# c71_DMC register map
Vendor: Texas Instruments
Peripheral module from a debugger description file (folder C71).
Registers are 64-bit, access per field, reset 0x0 unless marked. A register's access mark holds for its fields unless they carry their own. Offsets are as the file gives them; lines under a group give offsets from that group; [hi:lo] are bit positions; {n}, {i} and the like mark numbered series; 'fields as' and 'values as' point back to an identical list; <NAME> marks a mode.

## DMC(L1D) — Data Memory Controller
0x200 L1DCFG reset 0x7 — L1D Cache Configuration Register
  [2:0] L1DMODE rw — Controls the L1D Cache Size Mode
0x202 L1DWB — L1D Global Writeback Register
  [0] WB rw — Controls the Global Writeback of L1D Cache
0x203 L1DWBINV — L1D Global Writeback Invalidate Register
  [0] WBINV rw — Writeback and invalidate all lines L1D Cache
0x204 L1DINV — L1D Invalidate Register
  [0] INV rw — Controls the Global Invalidation of L1D Cache
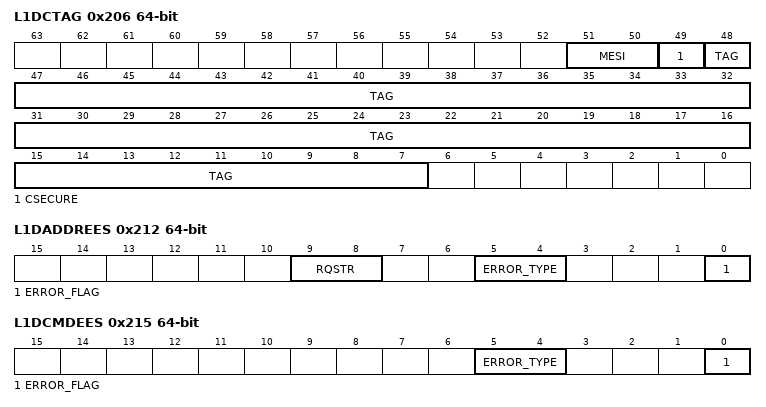
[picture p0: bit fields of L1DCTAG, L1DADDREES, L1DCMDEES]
0x206 L1DCTAG ro — L1D Cache tag View
  [51:50] MESI — MESI Bits includes valid and dirty bits
  [49] CSECURE — Secure bit
  [48:7] TAG
0x211 L1DADDREEA ro — L1D Addressing Error Event Address
  [43:0] EADDR — Transaction address for which error was detected
0x212 L1DADDREES ro — L1D Addressing Error Event Status
  [9:8] RQSTR — Requestor of the transaction for which error was detected \[CPU,DMA\]
  [5:4] ERROR_TYPE — Type of Error - Address outside implemented SRAM, SRAM under cache; LUT Base address outside implemented SRAM
  [0] ERROR_FLAG — Indicates that an address error occurred and has not been cleared yet. Clear occurs on a write to L1DADDREER
0x213 L1DADDREER — L1D Addressing Error Event Reset
  [0] ERROR_RESET wo — Clear error in L1DADDREES
0x214 L1DCMDEEA ro — L1D CMD Error Event Address
  [43:0] EADDR — Transaction address for which error was detected
0x215 L1DCMDEES ro — L1D CMD Error Event Status
  [5:4] ERROR_TYPE — CAS Operation failed; LUT Operation failed (invalid size or cfg)
  [0] ERROR_FLAG — Indicates that command error has occurred and has not been cleared yet. Clear occurs on a write to L1DCMDEER
0x216 L1DCMDEER — L1D CMD Error Event Reset
  [0] ERROR_RESET wo — Clear error in L1DCMDEES
